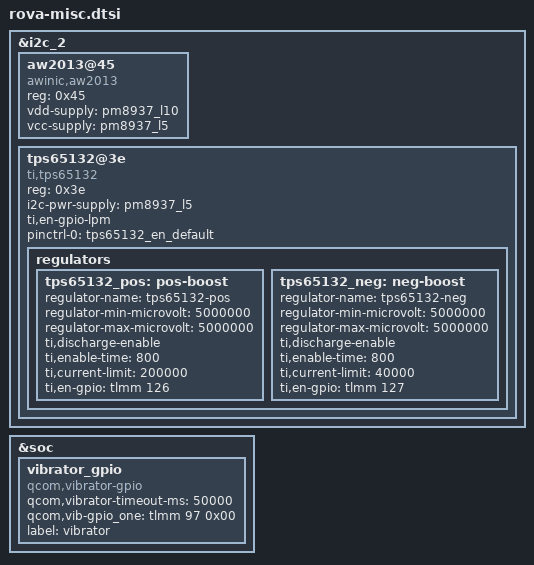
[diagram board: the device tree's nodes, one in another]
/*
 * Copyright (c) 2016, The Linux Foundation. All rights reserved.
 * Copyright (C) 2018 XiaoMi, Inc.
 *
 * This program is free software; you can redistribute it and/or modify
 * it under the terms of the GNU General Public License version 2 and
 * only version 2 as published by the Free Software Foundation.
 *
 * This program is distributed in the hope that it will be useful,
 * but WITHOUT ANY WARRANTY; without even the implied warranty of
 * MERCHANTABILITY or FITNESS FOR A PARTICULAR PURPOSE.  See the
 * GNU General Public License for more details.
 */

&i2c_2  {
	aw2013@45 {
		compatible = "awinic,aw2013";
		reg = <0x45>;
		vdd-supply = <&pm8937_l10>; //Power supply needed to power up the device
		vcc-supply = <&pm8937_l5>; //Power source required to power up i2c bus
	};
};

&soc {
	vibrator_gpio {
		compatible = "qcom,vibrator-gpio";
		qcom,vibrator-timeout-ms = <50000>;
		qcom,vib-gpio_one = <&tlmm 97 0x00>;
		label = "vibrator";
	};
};

&i2c_2 { /* i2c 2 */
	tps65132@3e {
		compatible = "ti,tps65132";
		reg = <0x3e>;
		i2c-pwr-supply = <&pm8937_l5>;
		ti,en-gpio-lpm;
		pinctrl-names = "default";
		pinctrl-0 = <&tps65132_en_default>;

		regulators {
			tps65132_pos: pos-boost {
				regulator-name = "tps65132-pos";
				regulator-min-microvolt = <5000000>;
				regulator-max-microvolt = <5000000>;
				ti,discharge-enable;
				ti,enable-time = <800>;
				ti,current-limit = <200000>;
				ti,en-gpio = <&tlmm 126 0>;
			};

			tps65132_neg: neg-boost {
				regulator-name = "tps65132-neg";
				regulator-min-microvolt = <5000000>;
				regulator-max-microvolt = <5000000>;
				ti,discharge-enable;
				ti,enable-time = <800>;
				ti,current-limit = <40000>;
				ti,en-gpio = <&tlmm 127 0>;
			};
		};
	};
};


